AUTOSAR XML (schema 00046)
package /RTE_EVENTS_LAB
  sender receiver interface SRIF_Inputs
    data Val1: type=uint16
    data Val2: type=uint16
  sender receiver interface SRIF_Output
    data SUM_Result: type=uint32
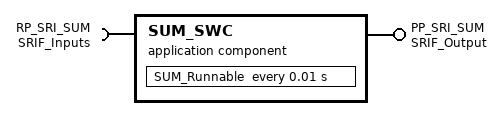
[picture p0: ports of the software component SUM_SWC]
  application sw component type SUM_SWC
    provide port PP_SRI_SUM: provided-interface=SRIF_Output
    require port RP_SRI_SUM: required-interface=SRIF_Inputs
    behavior SUM_SWC_Beh
      exclusive area EA1
      timing event TimingEvent_10ms: start-on-event=SUM_Runnable, period=0.01
      init event InitEvent: start-on-event=SUM_Runnable
      data received event DRC_Val1_Event: start-on-event=SUM_Runnable, data=Val1
      data write completed event DWC_SUM_Result_Event: start-on-event=SUM_Runnable, event-source=Result_Data
      runnable SUM_Runnable: symbol=SUM
        data-read-access:
          access Val1_Data: accessed-variable=RP_SRI_SUM.Val1
          access Val2_Data: accessed-variable=RP_SRI_SUM.Val2
        data-write-access:
          access Result_Data: accessed-variable=PP_SRI_SUM.SUM_Result
